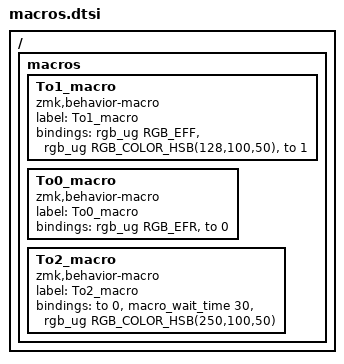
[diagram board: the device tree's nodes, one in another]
/ {
    macros {
        To1_macro: To1_macro {
            compatible = "zmk,behavior-macro";
            label = "To1_macro";
            #binding-cells = <0>;
            bindings = <&rgb_ug RGB_EFF &rgb_ug RGB_COLOR_HSB(128,100,50) &to 1>;
        };

        To0_macro: To0_macro {
            compatible = "zmk,behavior-macro";
            label = "To0_macro";
            #binding-cells = <0>;
            bindings = <&rgb_ug RGB_EFR &to 0>;
        };

        To2_macro: To2_macro {
            compatible = "zmk,behavior-macro";
            label = "To2_macro";
            #binding-cells = <0>;
            bindings =
                <&to 0>,
                <&macro_wait_time 30>,
                <&rgb_ug RGB_COLOR_HSB(250,100,50)>;
        };
    };
};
